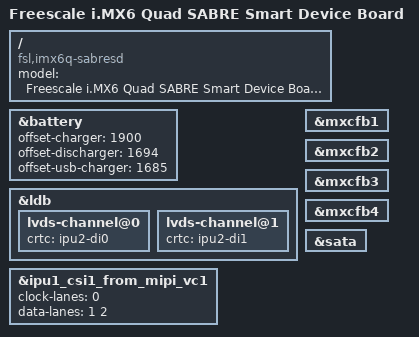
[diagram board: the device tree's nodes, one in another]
// SPDX-License-Identifier: GPL-2.0+
//
// Copyright 2012 Freescale Semiconductor, Inc.
// Copyright 2011 Linaro Ltd.

/dts-v1/;

#include "imx6q.dtsi"
#include "imx6qdl-sabresd.dtsi"

/ {
	model = "Freescale i.MX6 Quad SABRE Smart Device Board";
	compatible = "fsl,imx6q-sabresd", "fsl,imx6q";
};

&battery {
	offset-charger = <1900>;
	offset-discharger = <1694>;
	offset-usb-charger = <1685>;
};

&ldb {
	lvds-channel@0 {
		crtc = "ipu2-di0";
	};

	lvds-channel@1 {
		crtc = "ipu2-di1";
	};
};

&mxcfb1 {
	status = "okay";
};

&mxcfb2 {
	status = "okay";
};

&mxcfb3 {
	status = "okay";
};

&mxcfb4 {
	status = "okay";
};

&sata {
	status = "okay";
};

&ipu1_csi1_from_mipi_vc1 {
	clock-lanes = <0>;
	data-lanes = <1 2>;
};
